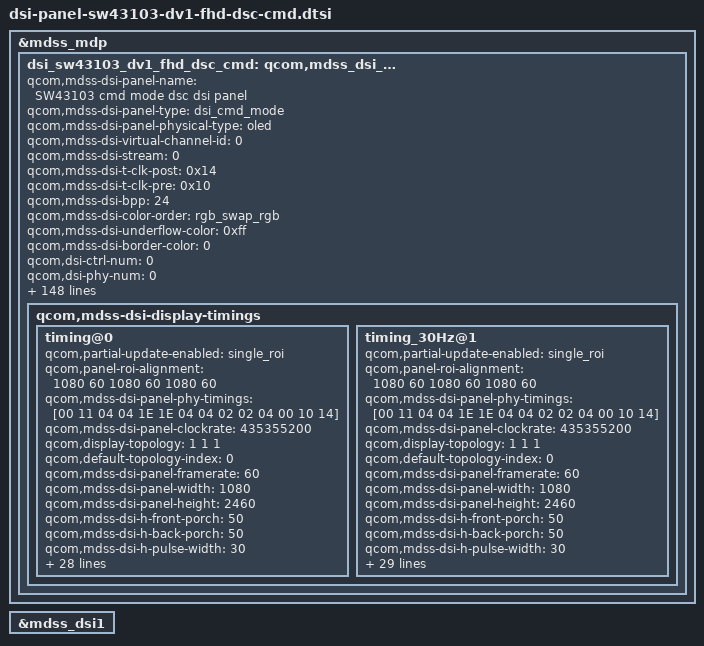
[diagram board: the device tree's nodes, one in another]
/* Copyright (c) 2014, Code Aurora Forum. All rights reserved.
 *
 * This program is free software; you can redistribute it and/or modify
 * it under the terms of the GNU General Public License version 2 and
 * only version 2 as published by the Free Software Foundation.
 *
 * This program is distributed in the hope that it will be useful,
 * but WITHOUT ANY WARRANTY; without even the implied warranty of
 * MERCHANTABILITY or FITNESS FOR A PARTICULAR PURPOSE.  See the
 * GNU General Public License for more details.
 */

&mdss_mdp {
    dsi_sw43103_dv1_fhd_dsc_cmd: qcom,mdss_dsi_sw43103_dv1_fhd_dsc_cmd {
		qcom,mdss-dsi-panel-name = "SW43103 cmd mode dsc dsi panel";
		qcom,mdss-dsi-panel-type = "dsi_cmd_mode";
		qcom,mdss-dsi-panel-physical-type = "oled";
		qcom,mdss-dsi-virtual-channel-id = <0>;
		qcom,mdss-dsi-stream = <0>;
		qcom,mdss-dsi-t-clk-post = <0x14>;
		qcom,mdss-dsi-t-clk-pre = <0x10>;
		qcom,mdss-dsi-bpp = <24>;
		qcom,mdss-dsi-color-order = "rgb_swap_rgb";
		qcom,mdss-dsi-underflow-color = <0xff>;
		qcom,mdss-dsi-border-color = <0>;
		qcom,dsi-ctrl-num = <0>;
		qcom,dsi-phy-num = <0>;
		qcom,dsi-select-clocks = "mux_byte_clk0", "mux_pixel_clk0";
		qcom,mdss-dsi-traffic-mode = "burst_mode";
		qcom,mdss-dsi-lane-map = "lane_map_0123";
		qcom,mdss-dsi-bllp-eof-power-mode;
		qcom,mdss-dsi-bllp-power-mode;
		qcom,mdss-dsi-lane-0-state;
		qcom,mdss-dsi-lane-1-state;
		qcom,mdss-dsi-lane-2-state;
		qcom,mdss-dsi-lane-3-state;
		qcom,mdss-dsi-reset-sequence = <1 10>, <0 2>, <1 10>;
		qcom,mdss-dsi-dma-trigger = "trigger_sw";
		qcom,mdss-dsi-mdp-trigger = "none";
		qcom,mdss-dsi-te-pin-select = <1>;
		qcom,panel-te-source = <0>;
		qcom,mdss-dsi-wr-mem-start = <0x2c>;
		qcom,mdss-dsi-wr-mem-continue = <0x3c>;
		qcom,mdss-dsi-te-dcs-command = <1>;
		qcom,mdss-dsi-lp11-init;
		qcom,mdss-dsi-tx-eot-append;
		qcom,ulps-enabled;
		//qcom,null-insertion-enabled;

		qcom,mdss-dsi-panel-hdr-enabled;
		qcom,mdss-dsi-panel-hdr-color-primaries = <14880 15935 32435 16555 14945 30910 7790 3415>;
		qcom,mdss-dsi-panel-peak-brightness = <5000000>;		/* max. 500nits */
		qcom,mdss-dsi-panel-blackness-level = <6134>;

		qcom,mdss-pan-physical-width-dimension = <69>;
		qcom,mdss-pan-physical-height-dimension = <158>;

		//lge,use-dim-ctrl;
		/* Brightness Map List */
		lge,blmap-daylight = <
			0
			5 5 5 5 5 5 5 5 5 5 6 7 8 10 11 12 13 14 15 17
			18 19 20 21 22 23 25 26 27 28 29 30 32 33 34 35 36 37 39 40
			41 42 43 45 46 47 48 49 51 52 53 54 55 57 58 59 60 61 63 64
			65 69 73 78 82 86 90 95 99 103 107 112 116 120 124 128 133 137 141 145
			150 154 158 163 167 171 175 180 184 189 193 197 202 206 211 215 219 224 228 233
			237 242 246 250 255 259 264 268 275 282 290 297 304 311 319 326 333 340 348 355
			362 369 376 384 391 398 405 413 420 427 434 442 449 456 464 471 479 486 494 501
			509 516 523 531 538 546 553 561 569 576 584 591 599 606 614 621 629 636 644 656
			668 680 692 704 716 728 740 752 764 776 788 800 812 824 836 848 860 872 884 896
			908 920 933 945 957 969 981 993 1005 1017 1029 1041 1053 1065 1077 1089 1101 1113 1125 1137
			1149 1161 1173 1185 1197 1209 1221 1230 1238 1247 1256 1265 1273 1282 1291 1299 1308 1317 1326 1334
			1343 1352 1361 1369 1378 1387 1395 1404 1413 1422 1430 1439 1448 1458 1467 1477 1486 1496 1505 1515
			1524 1534 1543 1553 1562 1572 1581 1591 1600 1610 1619 1629 1638 1648 1657 1661 1664 1668 1671 1675
			1678 1682 1685 1689 1692 1696 1700 1703 1707 1710 1714 1717 1721 1724 1728 1731 1735 1739 1742 1746
			1749 1753 1756 1760 1763 1767 1770 1774 1778 1781 1785 1788 1792 1795 1799 1802 1806 1809 1813 1817
			1820 1824 1827 1831 1834 1838 1841 1845 1848 1852 1856 1859 1863 1866 1870 1873 1877 1880 1884 1887
			1891 1895 1898 1902 1905 1909 1912 1916 1919 1923 1926 1930 1934 1937 1941 1944 1948 1951 1955 1958
			1962 1965 1969 1973 1976 1980 1983 1987 1990 1994 1997 2001 2004 2008 2012 2015 2019 2022 2026 2029
			2033 2036 2040 2043 2047
		>;
		lge,blmap-ve = <
			0
			5 5 5 5 5 5 5 5 5 5 6 7 8 10 11 12 13 14 15 17
			18 19 20 21 22 23 25 26 27 28 29 30 32 33 34 35 36 37 39 40
			41 42 43 45 46 47 48 49 51 52 53 54 55 57 58 59 60 61 63 64
			65 69 73 78 82 86 90 95 99 103 107 112 116 120 124 128 133 137 141 145
			150 154 158 163 167 171 175 180 184 189 193 197 202 206 211 215 219 224 228 233
			237 242 246 250 255 259 264 268 275 282 290 297 304 311 319 326 333 340 348 355
			362 369 376 384 391 398 405 413 420 427 434 442 449 456 464 471 479 486 494 501
			509 516 523 531 538 546 553 561 569 576 584 591 599 606 614 621 629 636 644 656
			668 680 692 704 716 728 740 752 764 776 788 800 812 824 836 848 860 872 884 896
			908 920 933 945 957 969 981 993 1005 1017 1029 1041 1053 1065 1077 1089 1101 1113 1125 1137
			1149 1161 1173 1185 1197 1209 1221 1230 1238 1247 1256 1265 1273 1282 1291 1299 1308 1317 1326 1334
			1343 1352 1361 1369 1378 1387 1395 1404 1413 1422 1430 1439 1448 1458 1467 1477 1486 1496 1505 1515
			1524 1534 1543 1553 1562 1572 1581 1591 1600 1610 1619 1629 1638 1648 1657 1661 1664 1668 1671 1675
			1678 1682 1685 1689 1692 1696 1700 1703 1707 1710 1714 1717 1721 1724 1728 1731 1735 1739 1742 1746
			1749 1753 1756 1760 1763 1767 1770 1774 1778 1781 1785 1788 1792 1795 1799 1802 1806 1809 1813 1817
			1820 1824 1827 1831 1834 1838 1841 1845 1848 1852 1856 1859 1863 1866 1870 1873 1877 1880 1884 1887
			1891 1895 1898 1902 1905 1909 1912 1916 1919 1923 1926 1930 1934 1937 1941 1944 1948 1951 1955 1958
			1962 1965 1969 1973 1976 1980 1983 1987 1990 1994 1997 2001 2004 2008 2012 2015 2019 2022 2026 2029
			2033 2036 2040 2043 2047
		>;
		lge,blmap-ex = <
			0
			16 16 16 16 16 16 16 16 16 25 35 44 53 62 72 81 90 99 109 118
			127 136 146 155 164 173 183 192 201 210 220 229 238 247 257 266 273 281 288 295
			303 310 317 325 332 339 347 354 361 369 376 383 391 398 405 413 420 427 435 442
			449 457 464 471 479 486 493 501 508 515 523 530 537 545 552 572 592 612 632 652
			672 692 712 732 752 772 792 812 832 852 872 892 912 932 952 972 992 1009 1026 1043
			1060 1076 1093 1110 1127 1144 1161 1178 1195 1212 1228 1245 1262 1279 1296 1310 1325 1339 1353 1368
			1382 1396 1411 1425 1439 1453 1468 1482 1496 1511 1525 1539 1554 1568 1568 1568 1568 1568 1568 1568
			1589 1611 1632 1653 1674 1696 1717 1738 1759 1781 1802 1823 1844 1866 1887 1908 1929 1951 1972 1972
			1972 1972 1972 1972 1972 1972 1972 1972 1972 1972 1972 1972 1972 1972 1972 1972 1972 1972 1972 1972
			1972 1972 1972 1972 1972 1972 1972 1972 1972 1972 1972 1972 1972 1972 1972 1972 1972 1972 1972 1972
			1972 1972 1972 1972 1972 1972 1972 1972 1972 1972 1972 1972 1972 1972 1972 1972 1972 1972 1972 1972
			1972 1972 1972 1972 1972 1972 1972 1972 1972 1972 1972 1972 1972 1972 1972 1972 1972 1972 1972 1972
			1972 1972 1972 1972 1972 1972 1972 1972 1972 1972 1972 1972 1972 1972 1972
		>;
		lge,blmap-hdr-daylight = <
			0
			5 5 5 5 5 5 5 5 5 5 6 7 8 10 11 12 13 14 15 17
			18 19 20 21 22 23 25 26 27 28 29 30 32 33 34 35 36 37 39 40
			41 42 43 45 46 47 48 49 51 52 53 54 55 57 58 59 60 61 63 64
			65 69 73 78 82 86 90 95 99 103 107 112 116 120 124 128 133 137 141 145
			150 154 158 163 167 171 175 180 184 189 193 197 202 206 211 215 219 224 228 233
			237 242 246 250 255 259 264 268 275 282 290 297 304 311 319 326 333 340 348 355
			362 369 376 384 391 398 405 413 420 427 434 442 449 456 464 471 479 486 494 501
			509 516 523 531 538 546 553 561 569 576 584 591 599 606 614 621 629 636 644 656
			668 680 692 704 716 728 740 752 764 776 788 800 812 824 836 848 860 872 884 896
			908 920 933 945 957 969 981 993 1005 1017 1029 1041 1053 1065 1077 1089 1101 1113 1125 1137
			1149 1161 1173 1185 1197 1209 1221 1230 1238 1247 1256 1265 1273 1282 1291 1299 1308 1317 1326 1334
			1343 1352 1361 1369 1378 1387 1395 1404 1413 1422 1430 1439 1448 1458 1467 1477 1486 1496 1505 1515
			1524 1534 1543 1553 1562 1572 1581 1591 1600 1610 1619 1629 1638 1648 1657 1661 1664 1668 1671 1675
			1678 1682 1685 1689 1692 1696 1700 1703 1707 1710 1714 1717 1721 1724 1728 1731 1735 1739 1742 1746
			1749 1753 1756 1760 1763 1767 1770 1774 1778 1781 1785 1788 1792 1795 1799 1802 1806 1809 1813 1817
			1820 1824 1827 1831 1834 1838 1841 1845 1848 1852 1856 1859 1863 1866 1870 1873 1877 1880 1884 1887
			1891 1895 1898 1902 1905 1909 1912 1916 1919 1923 1926 1930 1934 1937 1941 1944 1948 1951 1955 1958
			1962 1965 1969 1973 1976 1980 1983 1987 1990 1994 1997 2001 2004 2008 2012 2015 2019 2022 2026 2029
			2033 2036 2040 2043 2047
		>;
		lge,blmap = <
			0
			5 5 5 5 5 5 5 5 5 5 6 7 8 9 10 11 12 13 14 15
			16 17 18 18 19 20 21 22 23 24 25 26 27 28 29 30 31 32 33 34
			35 36 37 38 39 40 41 42 43 44 45 46 47 48 49 50 51 52 53 54
			55 59 62 66 69 73 77 80 84 87 91 94 98 102 105 109 112 116 120 123
			127 130 134 138 141 145 148 152 156 160 163 167 171 175 178 182 186 190 193 197
			201 205 208 212 216 220 223 227 233 240 246 252 258 265 271 277 283 290 296 302
			309 315 321 327 334 340 346 352 359 365 371 377 384 390 397 403 410 416 423 429
			436 442 448 455 461 468 475 481 488 494 501 507 514 520 527 533 540 546 553 563
			573 583 594 604 614 624 634 644 654 665 675 685 695 705 715 725 736 746 756 766
			776 786 797 807 817 827 837 847 857 868 878 888 898 908 918 928 939 949 959 969
			979 989 999 1010 1020 1030 1040 1049 1058 1067 1076 1085 1094 1103 1112 1122 1131 1140 1149 1158
			1167 1176 1185 1194 1203 1212 1221 1230 1239 1248 1257 1267 1276 1286 1296 1306 1316 1326 1335 1345
			1355 1365 1375 1385 1395 1404 1414 1424 1434 1444 1454 1463 1473 1483 1493 1498 1503 1508 1513 1518
			1523 1528 1533 1538 1543 1548 1553 1558 1564 1569 1574 1579 1584 1589 1594 1599 1604 1609 1614 1619
			1624 1629 1634 1639 1644 1649 1654 1659 1664 1669 1674 1679 1684 1689 1694 1699 1705 1710 1715 1720
			1725 1730 1735 1740 1745 1750 1755 1760 1765 1770 1775 1780 1785 1790 1795 1800 1805 1810 1815 1820
			1825 1830 1835 1841 1846 1851 1856 1861 1866 1871 1876 1881 1886 1891 1896 1901 1906 1911 1916 1921
			1926 1931 1936 1941 1946 1951 1956 1961 1966 1971 1976 1982 1987 1992 1997 2002 2007 2012 2017 2022
			2027 2032 2037 2042 2047
		>;
		lge,blmap-hdr = <
			0
			5 5 5 5 5 5 5 5 5 5 6 7 8 9 10 11 12 13 14 15
			16 17 18 18 19 20 21 22 23 24 25 26 27 28 29 30 31 32 33 34
			35 36 37 38 39 40 41 42 43 44 45 46 47 48 49 50 51 52 53 54
			55 59 62 66 69 73 77 80 84 87 91 94 98 102 105 109 112 116 120 123
			127 130 134 138 141 145 148 152 156 160 163 167 171 175 178 182 186 190 193 197
			201 205 208 212 216 220 223 227 233 240 246 252 258 265 271 277 283 290 296 302
			309 315 321 327 334 340 346 352 359 365 371 377 384 390 397 403 410 416 423 429
			436 442 448 455 461 468 475 481 488 494 501 507 514 520 527 533 540 546 553 563
			573 583 594 604 614 624 634 644 654 665 675 685 695 705 715 725 736 746 756 766
			776 786 797 807 817 827 837 847 857 868 878 888 898 908 918 928 939 949 959 969
			979 989 999 1010 1020 1030 1040 1049 1058 1067 1076 1085 1094 1103 1112 1122 1131 1140 1149 1158
			1167 1176 1185 1194 1203 1212 1221 1230 1239 1248 1257 1267 1276 1286 1296 1306 1316 1326 1335 1345
			1355 1365 1375 1385 1395 1404 1414 1424 1434 1444 1454 1463 1473 1483 1493 1498 1503 1508 1513 1518
			1523 1528 1533 1538 1543 1548 1553 1558 1564 1569 1574 1579 1584 1589 1594 1599 1604 1609 1614 1619
			1624 1629 1634 1639 1644 1649 1654 1659 1664 1669 1674 1679 1684 1689 1694 1699 1705 1710 1715 1720
			1725 1730 1735 1740 1745 1750 1755 1760 1765 1770 1775 1780 1785 1790 1795 1800 1805 1810 1815 1820
			1825 1830 1835 1841 1846 1851 1856 1861 1866 1871 1876 1881 1886 1891 1896 1901 1906 1911 1916 1921
			1926 1931 1936 1941 1946 1951 1956 1961 1966 1971 1976 1982 1987 1992 1997 2002 2007 2012 2017 2022
			2027 2032 2037 2042 2047
		>;

		lge,mdss-dsi-nolp-command = [
			15 01 00 00 28 00 02 53 84
			05 01 00 00 00 00 01 13
		];
		lge,mdss-dsi-nolp-command-state = "dsi_lp_mode";
		lge,mdss-dsi-lp2-command = [
			15 01 00 00 14 00 02 53 00
			05 01 00 00 00 00 01 12
		];
		lge,mdss-dsi-lp2-command-state = "dsi_lp_mode";

		lge,use-vr-lp-mode;
		lge,mdss-dsi-vr-lp-mode-on-command = [
			15 01 00 00 00 00 02 B0 A3
			39 01 00 00 00 00 08 B5 00 0B 00 3B 00 3B 10
			15 01 00 00 00 00 02 B0 CA
		];
		lge,mdss-dsi-vr-lp-mode-off-command = [
			15 01 00 00 00 00 02 B0 A3
			39 01 00 00 00 00 08 B5 00 3B 00 3B 00 3B 10
			15 01 00 00 00 00 02 B0 CA
		];
		lge,mdss-dsi-vr-lp-command-state = "dsi_lp_mode";
		lge,blmap-vr = < 0 165 >;

		lge,use-color-manager;
		lge,use-color-manager-oled;
		lge,color-manager-default-status = <1>;
		lge,mdss-dsi-color-manager-mode-table = <0 1>, <1 1>, <2 1>, <3 1>;
		lge,digital-gamma-absent;

		/* FP LHBM */
		lge,use-fp-lhbm;
		lge,use-fps-mode1-new;
		lge,mdss-dsi-fp-lhbm-ready-command = [
			15 01 00 00 00 00 02 53 A4
			39 00 00 00 00 00 03 51 05 53
			15 00 00 00 00 00 02 B0 A3
			39 00 00 00 00 00 1F B6 90 00 A1 80 F7 AA 90 00 A1 63 60 41 45 0D 94 26 BD E4 27 61 40 18 05 9C 08 A9 F8 09 A1 00
			15 01 00 00 00 00 02 B0 CA
		];
		lge,mdss-dsi-fp-lhbm-ready-command-state = "dsi_hs_mode";

		lge,mdss-dsi-fp-lhbm-exit-command = [
			15 01 00 00 00 00 02 53 84
			15 00 00 00 00 00 02 B0 A3
			39 00 00 00 00 00 1F B6 90 00 A1 80 F7 AA 71 B0 F1 63 60 41 45 0D 94 26 BD E4 27 61 40 18 05 9C 08 A9 F8 09 A1 00
			15 01 00 00 00 00 02 B0 CA
		];
		lge,mdss-dsi-fp-lhbm-exit-command-state = "dsi_hs_mode";

		lge,mdss-dsi-pre-fp-lhbm-on-command = [
			39 00 00 00 00 00 03 51 05 53
			15 00 00 00 00 00 02 B0 A3
			39 00 00 00 00 00 1F B6 90 00 A1 80 F7 AA 90 00 A1 63 60 41 45 0D 94 26 BD E4 27 61 40 18 05 9C 08 A9 F8 09 A1 00
			15 01 00 00 00 00 02 B0 CA
		];
		lge,mdss-dsi-pre-fp-lhbm-on-command-state = "dsi_hs_mode";

		lge,mdss-dsi-fp-lhbm-on-command = [
			39 01 00 00 00 00 03 51 05 53
			39 01 00 00 00 00 0B 55 08 08 72 D4 1C 61 0A 90 04 00
		];
		lge,mdss-dsi-fp-lhbm-on-command-state = "dsi_hs_mode";

		lge,mdss-dsi-fp-lhbm-off-command = [
			39 01 00 00 00 00 0B 55 08 00 72 D4 1C 61 0A 90 04 00
		];
		lge,mdss-dsi-fp-lhbm-off-command-state = "dsi_hs_mode";

		lge,mdss-dsi-post-fp-lhbm-off-command = [
			15 00 00 00 00 00 02 B0 A3
			39 00 00 00 00 00 1F B6 90 00 A1 80 F7 AA 71 B0 F1 63 60 41 45 0D 94 26 BD E4 27 61 40 18 05 9C 08 A9 F8 09 A1 00
			15 01 00 00 00 00 02 B0 CA
		];
		lge,mdss-dsi-post-fp-lhbm-off-command-state = "dsi_hs_mode";

		lge,mdss-dsi-fp-lhbm-aod-to-fps = [
			05 01 00 00 00 00 01 13 //Normal On
		];
		lge,mdss-dsi-fp-lhbm-aod-to-fps-state = "dsi_hs_mode";

		lge,mdss-dsi-fp-lhbm-fps-to-aod = [
			05 01 00 00 00 00 01 12 //AOD On
		];
		lge,mdss-dsi-fp-lhbm-fps-to-aod-state = "dsi_hs_mode";

		/* Screen Color Control */
		lge,mdss-dsi-disp-ctrl-command-1 = [
			15 01 00 00 00 00 02 B0 A1
			15 01 00 00 00 00 02 53 00
			15 01 00 00 00 00 02 B0 CA
		];
		lge,mdss-dsi-disp-ctrl-command-1-state = "dsi_hs_mode";

		lge,mdss-dsi-wb-default-command = [
			15 01 00 00 00 00 02 B0 A4
			39 01 00 00 00 00 0B B4 00 03 05 AF 03 05 AF 03 05 AF
			39 01 00 00 00 00 1C B5 00 FF 94 1F AE 37 AE 1F 94 00 FB 94 1E AD 35 AB 1C 90 00 DD 8F 16 9F 24 97 04 75
			15 01 00 00 00 00 02 B0 CA
		];
		lge,mdss-dsi-wb-default-command-state = "dsi_hs_mode";

		lge,digital-gamma-cmds-dummy = [
			15 01 00 00 00 00 02 B0 A4
			39 01 00 00 00 00 0B B4 00 03 05 AF 03 05 AF 03 05 AF
			39 01 00 00 00 00 1C B5 00 FF 94 1F AE 37 AE 1F 94 00 FB 94 1E AD 35 AB 1C 90 00 DD 8F 16 9F 24 97 04 75
			15 01 00 00 00 00 02 B0 CA
		];
		lge,digital-gamma-cmds-dummy-command = "dsi_hs_mode";

		lge,mdss-dsi-saturation-command = [
			15 01 00 00 00 00 02 B0 A4
			39 01 00 00 00 00 0D B9 35 2D 2D 37 34 35 36 36 36 2D 35 33
			15 01 00 00 00 00 02 B0 CA
		];
		lge,mdss-dsi-saturation-command-state = "dsi_hs_mode";

		lge,mdss-dsi-hue-command = [
			15 01 00 00 00 00 02 B0 A4
			39 01 00 00 00 00 0D BB 80 5A 7B 95 65 70 96 90 90 90 83 72
			15 01 00 00 00 00 02 B0 CA
		];
		lge,mdss-dsi-hue-command-state = "dsi_hs_mode";

		lge,mdss-dsi-sharpness-command = [
			15 01 00 00 00 00 02 B0 A4
			39 01 00 00 00 00 0C B2 89 1F 1F 88 24 68 22 20 04 00 00
			15 01 00 00 00 00 02 B0 CA
		];
		lge,mdss-dsi-sharpness-command-state = "dsi_hs_mode";

		lge,mdss-dsi-cm-natural = [
			15 01 00 00 00 00 02 B0 A4
			39 01 00 00 00 00 0B B4 00 03 05 AF 03 05 AF 03 05 AF
			39 01 00 00 00 00 1C B5 00 FF 94 1F AE 37 AE 1F 94 00 FB 94 1E AD 35 AB 1C 90 00 DD 8F 16 9F 24 97 04 75
			39 01 00 00 00 00 0D B7 80 80 80 80 80 80 80 80 80 80 80 80
			39 01 00 00 00 00 0D B8 80 80 80 80 80 80 80 80 80 80 80 80
			39 01 00 00 00 00 0D B9 35 2D 2D 37 34 35 36 36 36 2D 35 33
			39 01 00 00 00 00 0D BA 80 80 80 80 88 80 80 80 80 80 80 7D
			39 01 00 00 00 00 0D BB 80 5A 7B 95 65 70 96 90 90 90 83 72
			15 01 00 00 00 00 02 B0 CA
		];
		lge,mdss-dsi-cm-natural-state = "dsi_hs_mode";

		lge,mdss-dsi-cm-vivid = [
			15 01 00 00 00 00 02 B0 A4
			39 01 00 00 00 00 0B B4 00 03 05 AF 03 05 AF 03 05 AF
			39 01 00 00 00 00 1C B5 00 FF 90 22 B3 37 AE 1F 90 00 FF 8E 19 AC 34 AE 23 96 00 FF 90 1E AE 30 A6 13 88
			39 01 00 00 00 00 0D B7 80 80 80 80 80 80 80 80 80 80 80 80
			39 01 00 00 00 00 0D B8 80 80 80 80 80 80 80 80 80 80 80 80
			39 01 00 00 00 00 0D B9 43 43 43 3D 38 3E 43 43 43 43 46 46
			39 01 00 00 00 00 0D BA 80 80 80 80 80 80 80 80 80 80 80 80
			39 01 00 00 00 00 0D BB 80 80 80 80 7A 80 80 80 80 80 80 80
			15 01 00 00 00 00 02 B0 CA
		];
		lge,mdss-dsi-cm-vivid-state = "dsi_hs_mode";

		lge,mdss-dsi-cm-cinema = [
			15 01 00 00 00 00 02 B0 A4
			39 01 00 00 00 00 0B B4 00 03 05 AF 03 05 AF 03 05 AB
			39 01 00 00 00 00 1C B5 00 FF A1 26 AF 38 AF 20 95 00 EC 90 18 AF 31 A7 17 80 00 B3 8D 12 9A 14 84 F7 65
			39 01 00 00 00 00 0D B7 80 80 80 80 80 80 80 80 80 80 80 80
			39 01 00 00 00 00 0D B8 80 80 80 80 89 80 80 80 80 80 80 80
			39 01 00 00 00 00 0D B9 39 3A 36 3A 3D 38 3D 3A 3A 3A 35 35
			39 01 00 00 00 00 0D BA 80 80 80 80 88 80 80 80 80 80 7D 7D
			39 01 00 00 00 00 0D BB 6A 77 85 8B 75 70 86 85 85 80 5D 6F
			15 01 00 00 00 00 02 B0 CA
		];
		lge,mdss-dsi-cm-cinema-state = "dsi_hs_mode";

		/* Video Enahnacement */
		lge,mdss-dsi-ve-on-command = [
			15 01 00 00 00 00 02 53 84
			15 01 00 00 00 00 02 B0 A4
			39 01 00 00 00 00 0D B7 80 80 80 80 80 80 80 80 80 80 80 80
			39 01 00 00 00 00 0D B8 80 80 80 80 80 80 80 80 80 80 80 80
			39 01 00 00 00 00 0D B9 46 46 46 43 38 43 46 46 46 46 46 46
			39 01 00 00 00 00 0D BA 80 80 80 80 80 80 80 80 80 80 80 80
			39 01 00 00 00 00 0D BB 80 80 80 80 7A 80 80 80 80 80 80 80
			15 01 00 00 00 00 02 B0 CA
		];
		lge,mdss-dsi-ve-on-command-state = "dsi_hs_mode";

		lge,use-irc-ctrl;
		lge,mdss-dsi-irc-command = [
			15 01 00 00 00 00 02 B0 A5
			39 01 00 00 00 00 08 B1 60 C0 00 00 00 10 FF
			15 01 00 00 00 00 02 B0 CA
		];
		lge,mdss-dsi-irc-command-state = "dsi_hs_mode";

		lge,use-ace-ctrl;
		lge,default-ace-mode = <0>;
		lge,mdss-dsi-ace-tune-command = [
			15 01 00 00 00 00 02 B0 A4
			39 01 00 00 00 00 0C B2 89 3F 2F 88 88 88 33 20 04 00 00
			39 01 00 00 00 00 07 B3 00 80 FF 88 08 93
			15 01 00 00 00 00 02 B0 A1
			15 01 00 00 00 00 02 53 14
			39 01 00 00 00 00 02 55 28
			15 01 00 00 00 00 02 B0 CA
		];
		lge,mdss-dsi-ace-restore-command = [
			15 01 00 00 00 00 02 B0 A1
			39 01 00 00 00 00 02 55 08
			15 01 00 00 00 00 02 B0 CA
		];
		lge,mdss-dsi-ace-command-state = "dsi_hs_mode";

		/* tc Perf */
		lge,use-tc-perf;
		lge,mdss-dsi-tc-perf-on-command = [
			15 01 00 00 00 00 02 B0 A3
			39 01 00 00 00 00 1F B6 90 00 A1 90 00 A1 71 B0 F1 63 60 41 45 0D 94 26 BD E4 27 61 40 18 05 9C 08 A9 F8 09 A1 00
			15 01 00 00 00 00 02 B0 CA
		];
		lge,mdss-dsi-tc-perf-on-command-state = "dsi_hs_mode";

		lge,mdss-dsi-tc-perf-off-command = [
			15 01 00 00 00 00 02 B0 A3
			39 01 00 00 00 00 1F B6 90 00 A1 80 F7 AA 71 B0 F1 63 60 41 45 0D 94 26 BD E4 27 61 40 18 05 9C 08 A9 F8 09 A1 00
			15 01 00 00 00 00 02 B0 CA
		];
		lge,mdss-dsi-tc-perf-off-command-state = "dsi_hs_mode";

		qcom,mdss-dsi-display-timings {
			timing@0{
				qcom,partial-update-enabled = "single_roi";
				qcom,panel-roi-alignment = <1080 60 1080 60 1080 60>;
				qcom,mdss-dsi-panel-phy-timings = [00 11 04 04 1E 1E 04 04 02 02 04 00 10 14];
				qcom,mdss-dsi-panel-clockrate = <435355200>;
				qcom,display-topology = <1 1 1>;
				qcom,default-topology-index = <0>;
				qcom,mdss-dsi-panel-framerate = <60>;
				qcom,mdss-dsi-panel-width = <1080>;
				qcom,mdss-dsi-panel-height = <2460>;
				qcom,mdss-dsi-h-front-porch = <50>;
				qcom,mdss-dsi-h-back-porch = <50>;
				qcom,mdss-dsi-h-pulse-width = <30>;
				qcom,mdss-dsi-h-sync-skew = <0>;
				qcom,mdss-dsi-v-back-porch = <2>;
				qcom,mdss-dsi-v-front-porch = <4>;
				qcom,mdss-dsi-v-pulse-width = <2>;
				qcom,mdss-dsi-h-left-border = <0>;
				qcom,mdss-dsi-h-right-border = <0>;
				qcom,mdss-dsi-v-top-border = <0>;
				qcom,mdss-dsi-v-bottom-border = <0>;
				qcom,mdss-dsi-h-sync-pulse = <0>;
				//qcom,mdss-mdp-transfer-time-us = <15000>;

				qcom,mdss-dsi-on-command = [
					15 01 00 00 00 00 02 B0 A1
					39 01 00 00 00 00 05 2A 00 00 04 37
					39 01 00 00 00 00 05 2B 00 00 09 9B
					15 01 00 00 00 00 02 55 08
					39 01 00 00 00 00 05 30 00 00 09 9B
					39 01 00 00 00 00 05 31 00 00 04 37
					15 01 00 00 00 00 02 35 00
					15 01 00 00 00 00 02 B0 CA
					05 01 00 00 64 00 01 11

					15 01 00 00 00 00 02 B0 A3
					39 01 00 00 00 00 05 EE 02 00 00 00
					39 01 00 00 00 00 03 BF 00 23

					15 01 00 00 00 00 02 B0 A2
					39 01 00 00 00 00 06 B7 30 0F 0F 00 10

					15 01 00 00 00 00 02 B0 A3
					39 01 00 00 00 00 06 B3 1F 63 00 00 06

					15 01 00 00 00 00 02 B0 A5
					39 01 00 00 00 00 1E CD 10 12 01 5A 90 00 00 00 00 00 61 00 01 01 00 01 11 40 00 00 00 00 3F FF FF FF 70 FF 00 //Green Circle

					15 01 00 00 00 00 02 B0 A6
					39 01 00 00 00 00 05 FC 00 00 41 40

					15 01 00 00 00 00 02 53 84
					15 01 00 00 00 00 02 B0 A4
					39 01 00 00 00 00 0B B4 00 03 05 AF 03 05 AF 03 05 AF
					39 01 00 00 00 00 1C B5 00 FF 94 1F AE 37 AE 1F 94 00 FB 94 1E AD 35 AB 1C 90 00 DD 8F 16 9F 24 97 04 75
					39 01 00 00 00 00 0D B7 80 80 80 80 80 80 80 80 80 80 80 80
					39 01 00 00 00 00 0D B8 80 80 80 80 80 80 80 80 80 80 80 80
					39 01 00 00 00 00 0D B9 35 2D 2D 37 34 35 36 36 36 2D 35 33
					39 01 00 00 00 00 0D BA 80 80 80 80 88 80 80 80 80 80 80 7D
					39 01 00 00 00 00 0D BB 80 5A 7B 95 65 70 96 90 90 90 83 72

					15 01 00 00 00 00 02 B0 A1
					39 01 00 00 00 00 03 C1 88 C8

					15 01 00 00 00 00 02 B0 CA

					05 01 00 00 14 00 01 29
				];

				qcom,mdss-dsi-off-command = [
					05 01 00 00 46 00 01 13
					05 01 00 00 00 00 01 28
					05 01 00 00 46 00 01 10
				];

				qcom,compression-mode = "dsc";
				qcom,mdss-dsc-version = <0x11>;
				qcom,mdss-dsc-scr-version = <0x1>;
				qcom,mdss-dsc-slice-height = <60>;
				qcom,mdss-dsc-slice-width = <540>;
				qcom,mdss-dsc-slice-per-pkt = <2>;
				qcom,mdss-dsc-bit-per-component = <8>;
				qcom,mdss-dsc-bit-per-pixel = <8>;
				qcom,lm-split = <540 540>;
				qcom,mdss-dsc-encoders = <2>;
				qcom,mdss-dsc-block-prediction-enable;

				qcom,mdss-dsi-on-command-state = "dsi_lp_mode";
				qcom,mdss-dsi-off-command-state = "dsi_lp_mode";

				qcom,mode-control-dsi-state = "dsi_lp_mode";
				qcom,mdss-dsi-pps-command-state = "dsi_hs_mode";
			};

			timing_30Hz@1{
				qcom,partial-update-enabled = "single_roi";
				qcom,panel-roi-alignment = <1080 60 1080 60 1080 60>;
				qcom,mdss-dsi-panel-phy-timings = [00 11 04 04 1E 1E 04 04 02 02 04 00 10 14];
				qcom,mdss-dsi-panel-clockrate = <435355200>;
				qcom,display-topology = <1 1 1>;
				qcom,default-topology-index = <0>;
				qcom,mdss-dsi-panel-framerate = <60>;
				qcom,mdss-dsi-panel-width = <1080>;
				qcom,mdss-dsi-panel-height = <2460>;
				qcom,mdss-dsi-h-front-porch = <50>;
				qcom,mdss-dsi-h-back-porch = <50>;
				qcom,mdss-dsi-h-pulse-width = <30>;
				qcom,mdss-dsi-h-sync-skew = <0>;
				qcom,mdss-dsi-v-back-porch = <2>;
				qcom,mdss-dsi-v-front-porch = <4>;
				qcom,mdss-dsi-v-pulse-width = <2>;
				qcom,mdss-dsi-h-left-border = <0>;
				qcom,mdss-dsi-h-right-border = <0>;
				qcom,mdss-dsi-v-top-border = <0>;
				qcom,mdss-dsi-v-bottom-border = <0>;
				qcom,mdss-dsi-h-sync-pulse = <0>;
				//qcom,mdss-mdp-transfer-time-us = <15000>;
				lge,mdss-dsi-panel-framerate-div = <2>;

				qcom,mdss-dsi-on-command = [
					15 01 00 00 00 00 02 B0 A1
					39 01 00 00 00 00 05 2A 00 00 04 37
					39 01 00 00 00 00 05 2B 00 00 09 9B
					15 01 00 00 00 00 02 55 08
					39 01 00 00 00 00 05 30 00 00 09 9B
					39 01 00 00 00 00 05 31 00 00 04 37
					15 01 00 00 00 00 02 35 00
					15 01 00 00 00 00 02 B0 CA
					05 01 00 00 64 00 01 11

					15 01 00 00 00 00 02 B0 A3
					39 01 00 00 00 00 05 EE 02 00 00 00
					39 01 00 00 00 00 03 BF 00 23

					15 01 00 00 00 00 02 B0 A2
					39 01 00 00 00 00 06 B7 30 0F 0F 00 10

					15 01 00 00 00 00 02 B0 A3
					39 01 00 00 00 00 06 B3 1F 63 00 00 06

					15 01 00 00 00 00 02 B0 A5
					39 01 00 00 00 00 1E CD 10 12 01 5A 90 00 00 00 00 00 61 00 01 01 00 01 11 40 00 00 00 00 3F FF FF FF 70 FF 00 //Green Circle

					15 01 00 00 00 00 02 B0 A6
					39 01 00 00 00 00 05 FC 00 00 41 40

					15 01 00 00 00 00 02 53 84
					15 01 00 00 00 00 02 B0 A4
					39 01 00 00 00 00 0B B4 00 03 05 AF 03 05 AF 03 05 AF
					39 01 00 00 00 00 1C B5 00 FF 94 1F AE 37 AE 1F 94 00 FB 94 1E AD 35 AB 1C 90 00 DD 8F 16 9F 24 97 04 75
					39 01 00 00 00 00 0D B7 80 80 80 80 80 80 80 80 80 80 80 80
					39 01 00 00 00 00 0D B8 80 80 80 80 80 80 80 80 80 80 80 80
					39 01 00 00 00 00 0D B9 35 2D 2D 37 34 35 36 36 36 2D 35 33
					39 01 00 00 00 00 0D BA 80 80 80 80 88 80 80 80 80 80 80 7D
					39 01 00 00 00 00 0D BB 80 5A 7B 95 65 70 96 90 90 90 83 72

					15 01 00 00 00 00 02 B0 A1
					39 01 00 00 00 00 03 C1 88 C8

					15 01 00 00 00 00 02 B0 CA

					05 01 00 00 14 00 01 29
				];

				qcom,mdss-dsi-off-command = [
					05 01 00 00 46 00 01 13
					05 01 00 00 00 00 01 28
					05 01 00 00 46 00 01 10
				];

				qcom,compression-mode = "dsc";
				qcom,mdss-dsc-version = <0x11>;
				qcom,mdss-dsc-scr-version = <0x1>;
				qcom,mdss-dsc-slice-height = <60>;
				qcom,mdss-dsc-slice-width = <540>;
				qcom,mdss-dsc-slice-per-pkt = <2>;
				qcom,mdss-dsc-bit-per-component = <8>;
				qcom,mdss-dsc-bit-per-pixel = <8>;
				qcom,lm-split = <540 540>;
				qcom,mdss-dsc-encoders = <2>;
				qcom,mdss-dsc-block-prediction-enable;

				qcom,mdss-dsi-on-command-state = "dsi_lp_mode";
				qcom,mdss-dsi-off-command-state = "dsi_lp_mode";

				qcom,mode-control-dsi-state = "dsi_lp_mode";
				qcom,mdss-dsi-pps-command-state = "dsi_hs_mode";
			};

		};
	};
};

&mdss_dsi1 {
	status = "ok";
};
